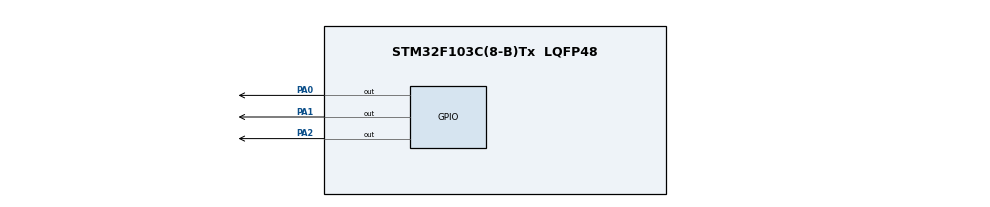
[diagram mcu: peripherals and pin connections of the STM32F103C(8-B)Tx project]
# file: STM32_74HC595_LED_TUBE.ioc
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Mcu.Family=STM32F1
Mcu.Name=STM32F103C(8-B)Tx
Mcu.Package=LQFP48
NVIC.PriorityGroup=NVIC_PRIORITYGROUP_4
NVIC.TIM2_IRQn=true\:0\:0\:false\:false\:true
PA0-WKUP.Signal=GPIO_Output
PA1.Signal=GPIO_Output
PA13.Mode=Serial_Wire
PA13.Signal=SYS_JTMS-SWDIO
PA14.Mode=Serial_Wire
PA14.Signal=SYS_JTCK-SWCLK
PA2.Signal=GPIO_Output
ProjectManager.HeapSize=0x200
ProjectManager.StackSize=0x400
ProjectManager.TargetToolchain=Makefile
RCC.APB1CLKDivider=RCC_HCLK_DIV4
RCC.APB1Freq_Value=2000000
RCC.APB1TimFreq_Value=4000000
RCC.APB2Freq_Value=8000000
RCC.APB2TimFreq_Value=8000000
TIM2.Period=49
TIM2.Prescaler=7999
TIM2.TIM_MasterOutputTrigger=TIM_TRGO_UPDATE
VP_TIM2_VS_ClockSourceINT.Mode=Internal

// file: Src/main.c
/**
  ******************************************************************************
  * File Name          : main.c
  * Description        : Main program body
  ******************************************************************************
  ** This notice applies to any and all portions of this file
  * that are not between comment pairs USER CODE BEGIN and
  * USER CODE END. Other portions of this file, whether
  * inserted by the user or by software development tools
  * are owned by their respective copyright owners.
  *
  * COPYRIGHT(c) 2017 STMicroelectronics
  *
  * Redistribution and use in source and binary forms, with or without modification,
  * are permitted provided that the following conditions are met:
  *   1. Redistributions of source code must retain the above copyright notice,
  *      this list of conditions and the following disclaimer.
  *   2. Redistributions in binary form must reproduce the above copyright notice,
  *      this list of conditions and the following disclaimer in the documentation
  *      and/or other materials provided with the distribution.
  *   3. Neither the name of STMicroelectronics nor the names of its contributors
  *      may be used to endorse or promote products derived from this software
  *      without specific prior written permission.
  *
  * THIS SOFTWARE IS PROVIDED BY THE COPYRIGHT HOLDERS AND CONTRIBUTORS "AS IS"
  * AND ANY EXPRESS OR IMPLIED WARRANTIES, INCLUDING, BUT NOT LIMITED TO, THE
  * IMPLIED WARRANTIES OF MERCHANTABILITY AND FITNESS FOR A PARTICULAR PURPOSE ARE
  * DISCLAIMED. IN NO EVENT SHALL THE COPYRIGHT HOLDER OR CONTRIBUTORS BE LIABLE
  * FOR ANY DIRECT, INDIRECT, INCIDENTAL, SPECIAL, EXEMPLARY, OR CONSEQUENTIAL
  * DAMAGES (INCLUDING, BUT NOT LIMITED TO, PROCUREMENT OF SUBSTITUTE GOODS OR
  * SERVICES; LOSS OF USE, DATA, OR PROFITS; OR BUSINESS INTERRUPTION) HOWEVER
  * CAUSED AND ON ANY THEORY OF LIABILITY, WHETHER IN CONTRACT, STRICT LIABILITY,
  * OR TORT (INCLUDING NEGLIGENCE OR OTHERWISE) ARISING IN ANY WAY OUT OF THE USE
  * OF THIS SOFTWARE, EVEN IF ADVISED OF THE POSSIBILITY OF SUCH DAMAGE.
  *
  ******************************************************************************
  */
#include "main.h"
#include "stm32f1xx_hal.h"

/* USER CODE BEGIN Includes */
#include "74HC595.c"
#include "main.h"

#define PORT GPIOA
#define pinCLK GPIO_PIN_0
#define pinCS  GPIO_PIN_1
#define pinDIN GPIO_PIN_2
/* USER CODE END Includes */

TIM_HandleTypeDef htim2;

/* USER CODE BEGIN PV */
/* Private variables ---------------------------------------------------------*/
long num;
uint8_t tim2_counter;
float tim2_Period;
/* USER CODE END PV */

void SystemClock_Config(void);
static void MX_GPIO_Init(void);
static void MX_TIM2_Init(void);

/* USER CODE BEGIN PFP */
/* Private function prototypes -----------------------------------------------*/

/* USER CODE END PFP */

/* USER CODE BEGIN 0 */

void counter()
{
  float i;
  for (i=1; i<999; i++)
  {
    //pre_send(LEDtab[i], 0b1111); // display number 0b0110
    digit4_3(i*1, 10, true);
    HAL_Delay(1);
  }
  return;
}

/* USER CODE END 0 */

int main(void)
{

  /* USER CODE BEGIN 1 */
  // 74HC595_init(pinCLK, pinDIN, pinCS);
  /* USER CODE END 1 */

  /* MCU Configuration----------------------------------------------------------*/

  /* Reset of all peripherals, Initializes the Flash interface and the Systick. */
  HAL_Init();

  /* Configure the system clock */
  SystemClock_Config();

  /* Initialize all configured peripherals */
  MX_GPIO_Init();
  MX_TIM2_Init();

  /* Infinite loop */
  while (1)
  {

  /* USER CODE BEGIN 3 */
    counter();
  }
  /* USER CODE END 3 */

}

/** System Clock Configuration
*/
void SystemClock_Config(void)
{

  RCC_OscInitTypeDef RCC_OscInitStruct;
  RCC_ClkInitTypeDef RCC_ClkInitStruct;

    /**Initializes the CPU, AHB and APB busses clocks
    */
  RCC_OscInitStruct.OscillatorType = RCC_OSCILLATORTYPE_HSI;
  RCC_OscInitStruct.HSIState = RCC_HSI_ON;
  RCC_OscInitStruct.HSICalibrationValue = 16;
  RCC_OscInitStruct.PLL.PLLState = RCC_PLL_NONE;
  if (HAL_RCC_OscConfig(&RCC_OscInitStruct) != HAL_OK)
  {
    _Error_Handler(__FILE__, __LINE__);
  }

    /**Initializes the CPU, AHB and APB busses clocks
    */
  RCC_ClkInitStruct.ClockType = RCC_CLOCKTYPE_HCLK|RCC_CLOCKTYPE_SYSCLK
                              |RCC_CLOCKTYPE_PCLK1|RCC_CLOCKTYPE_PCLK2;
  RCC_ClkInitStruct.SYSCLKSource = RCC_SYSCLKSOURCE_HSI;
  RCC_ClkInitStruct.AHBCLKDivider = RCC_SYSCLK_DIV1;
  RCC_ClkInitStruct.APB1CLKDivider = RCC_HCLK_DIV4;
  RCC_ClkInitStruct.APB2CLKDivider = RCC_HCLK_DIV1;

  if (HAL_RCC_ClockConfig(&RCC_ClkInitStruct, FLASH_LATENCY_0) != HAL_OK)
  {
    _Error_Handler(__FILE__, __LINE__);
  }

    /**Configure the Systick interrupt time
    */
  HAL_SYSTICK_Config(HAL_RCC_GetHCLKFreq()/1000);

    /**Configure the Systick
    */
  HAL_SYSTICK_CLKSourceConfig(SYSTICK_CLKSOURCE_HCLK);

  /* SysTick_IRQn interrupt configuration */
  HAL_NVIC_SetPriority(SysTick_IRQn, 0, 0);
}

/* TIM2 init function */
static void MX_TIM2_Init(void)
{

  TIM_ClockConfigTypeDef sClockSourceConfig;
  TIM_MasterConfigTypeDef sMasterConfig;

  htim2.Instance = TIM2;
  htim2.Init.Prescaler = 7999;
  htim2.Init.CounterMode = TIM_COUNTERMODE_UP;
  htim2.Init.Period = 49;
  htim2.Init.ClockDivision = TIM_CLOCKDIVISION_DIV1;
  if (HAL_TIM_Base_Init(&htim2) != HAL_OK)
  {
    _Error_Handler(__FILE__, __LINE__);
  }

  sClockSourceConfig.ClockSource = TIM_CLOCKSOURCE_INTERNAL;
  if (HAL_TIM_ConfigClockSource(&htim2, &sClockSourceConfig) != HAL_OK)
  {
    _Error_Handler(__FILE__, __LINE__);
  }

  sMasterConfig.MasterOutputTrigger = TIM_TRGO_UPDATE;
  sMasterConfig.MasterSlaveMode = TIM_MASTERSLAVEMODE_DISABLE;
  if (HAL_TIMEx_MasterConfigSynchronization(&htim2, &sMasterConfig) != HAL_OK)
  {
    _Error_Handler(__FILE__, __LINE__);
  }

}

/** Configure pins as
        * Analog
        * Input
        * Output
        * EVENT_OUT
        * EXTI
*/
static void MX_GPIO_Init(void)
{

  GPIO_InitTypeDef GPIO_InitStruct;

  /* GPIO Ports Clock Enable */
  __HAL_RCC_GPIOA_CLK_ENABLE();

  /*Configure GPIO pin Output Level */
  HAL_GPIO_WritePin(GPIOA, GPIO_PIN_0|GPIO_PIN_1|GPIO_PIN_2, GPIO_PIN_RESET);

  /*Configure GPIO pins : PA0 PA1 PA2 */
  GPIO_InitStruct.Pin = GPIO_PIN_0|GPIO_PIN_1|GPIO_PIN_2;
  GPIO_InitStruct.Mode = GPIO_MODE_OUTPUT_PP;
  GPIO_InitStruct.Speed = GPIO_SPEED_FREQ_LOW;
  HAL_GPIO_Init(GPIOA, &GPIO_InitStruct);

}

void _Error_Handler(char * file, int line)
{
  while(1)
  {
  }
}

/************************ (C) COPYRIGHT STMicroelectronics *****END OF FILE****/
